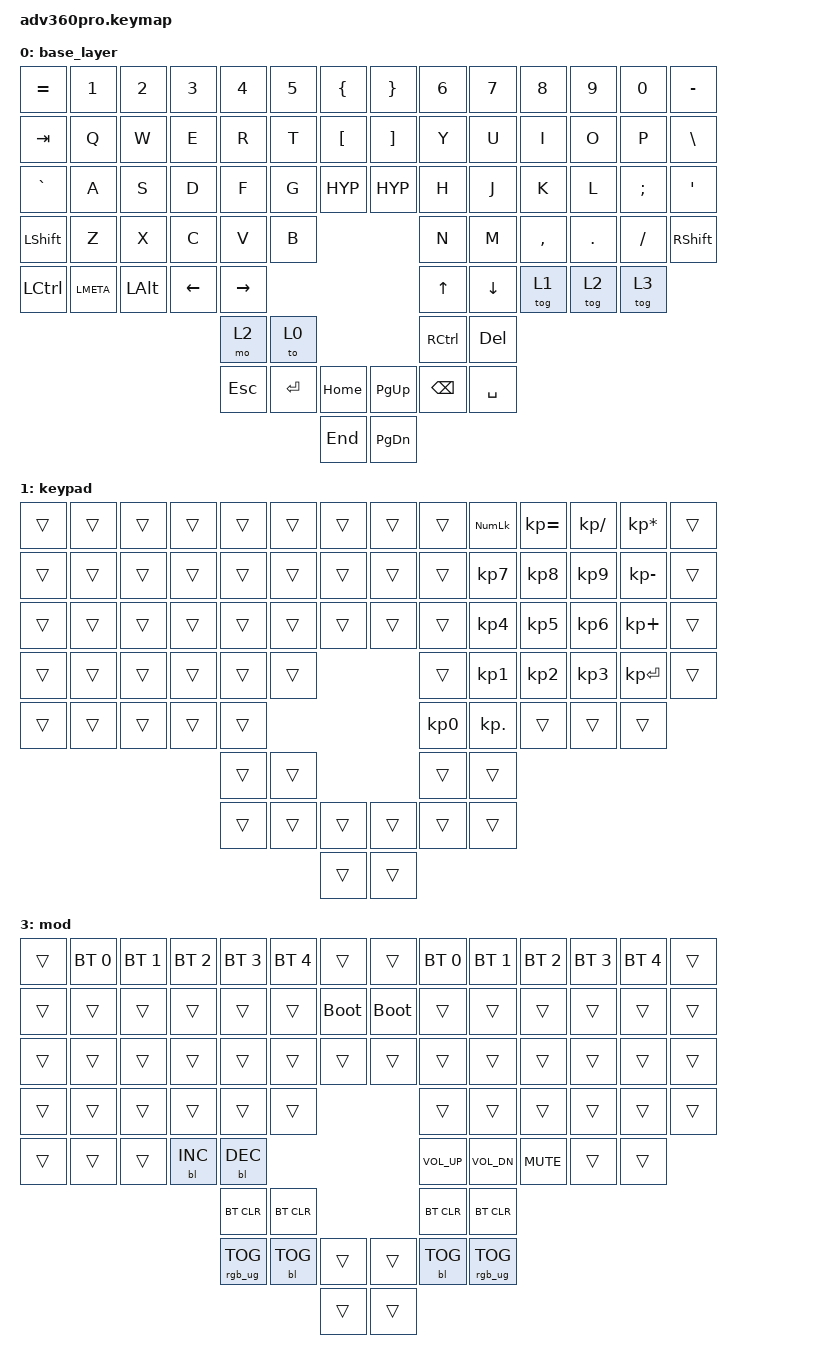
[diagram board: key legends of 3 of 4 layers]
#include <behaviors.dtsi>
#include <dt-bindings/zmk/keys.h>
#include <dt-bindings/zmk/bt.h>
#include <dt-bindings/zmk/outputs.h>
#include <dt-bindings/zmk/rgb.h>
#include <dt-bindings/zmk/backlight.h>

#define ___ &trans
#define HYP LS(LC(LA(LGUI)))

/ {
    /* remove unused keys from layout and move thumb cluster to bottom */
    chosen {
        zmk,matrix_transform = &urobs_transform;
    };

    keymap {
        compatible = "zmk,keymap";

        base_layer {
            bindings = <
                &kp EQUAL &kp N1    &kp N2    &kp N3    &kp N4    &kp N5    &kp LBRC       &kp RBRC  &kp N6    &kp N7    &kp N8    &kp N9    &kp N0    &kp MINUS
                &kp TAB   &kp Q     &kp W     &kp E     &kp R     &kp T     &kp LBKT       &kp RBKT  &kp Y     &kp U     &kp I     &kp O     &kp P     &kp BSLH
                &kp GRAVE &kp A     &kp S     &kp D     &kp F     &kp G     &kp HYP        &kp HYP   &kp H     &kp J     &kp K     &kp L     &kp SEMI  &kp SQT
                &kp LSHFT &kp Z     &kp X     &kp C     &kp V     &kp B                              &kp N     &kp M     &kp COMMA &kp DOT   &kp FSLH  &kp RSHFT
                &kp LCTRL &kp LMETA &kp LALT  &kp LEFT  &kp RIGHT                                    &kp UP    &kp DOWN  &tog 1    &tog 2    &tog 3
                                                        &mo 2     &to 0                              &kp RCTRL &kp DEL
                                                        &kp ESC   &kp RET   &kp HOME       &kp PG_UP &kp BSPC  &kp SPACE
                                                                            &kp END        &kp PG_DN
            >;
        };

        keypad {
            bindings = <
                ___       ___       ___       ___       ___       ___       ___            ___       ___       &kp KP_NUM &kp KP_EQUAL &kp KP_DIVIDE &kp KP_MULTIPLY ___
                ___       ___       ___       ___       ___       ___       ___            ___       ___       &kp KP_N7  &kp KP_N8    &kp KP_N9     &kp KP_MINUS    ___
                ___       ___       ___       ___       ___       ___       ___            ___       ___       &kp KP_N4  &kp KP_N5    &kp KP_N6     &kp KP_PLUS     ___
                ___       ___       ___       ___       ___       ___                                ___       &kp KP_N1  &kp KP_N2    &kp KP_N3     &kp KP_ENTER    ___
                ___       ___       ___       ___       ___                                                    &kp KP_N0  &kp KP_DOT   ___           ___             ___
                                                        ___       ___                                ___       ___
                                                        ___       ___       ___            ___       ___       ___
                                                                            ___            ___
            >;
        };

        fn {
            bindings = <
                &kp F1    &kp F2    &kp F3    &kp F4    &kp F5    &kp F6    ___            ___       &kp F7    &kp F8    &kp F9    &kp F10   &kp F11   &kp F12
                ___       ___       ___       ___       ___       ___       ___            ___       ___       ___       ___       ___       ___       ___
                ___       ___       ___       ___       ___       ___       ___            ___       ___       ___       ___       ___       ___       ___
                ___       ___       ___       ___       ___       ___       ___            ___       ___       ___       ___       ___       ___       ___
                ___       ___       ___       ___       ___       ___                                ___       ___       ___       ___       ___       ___
                ___       ___       ___       ___       ___                                                    ___       ___       ___       ___       ___
                                                        ___       ___                                ___       ___
                                                        ___       ___       ___            ___       ___       ___
                                                                            ___            ___
            >;
        };

        mod {
            bindings = <
                ___       &bt BT_SEL 0 &bt BT_SEL 1 &bt BT_SEL 2 &bt BT_SEL 3    &bt BT_SEL 4 ___              ___         &bt BT_SEL 0 &bt BT_SEL 1     &bt BT_SEL 2 &bt BT_SEL 3 &bt BT_SEL 4 ___
                ___       ___          ___          ___          ___             ___          &bootloader      &bootloader ___          ___              ___          ___          ___          ___
                ___       ___          ___          ___          ___             ___          ___              ___         ___          ___              ___          ___          ___          ___
                ___       ___          ___          ___          ___             ___                                       ___          ___              ___          ___          ___          ___
                ___       ___          ___          &bl BL_INC   &bl BL_DEC                                                             &kp C_VOL_UP     &kp C_VOL_DN &kp C_MUTE   ___          ___
                                                                 &bt BT_CLR      &bt BT_CLR                                &bt BT_CLR   &bt BT_CLR
                                                                 &rgb_ug RGB_TOG &bl BL_TOG   ___              ___         &bl BL_TOG   &rgb_ug RGB_TOG
                                                                                              ___              ___
            >;
        };

    };

};
